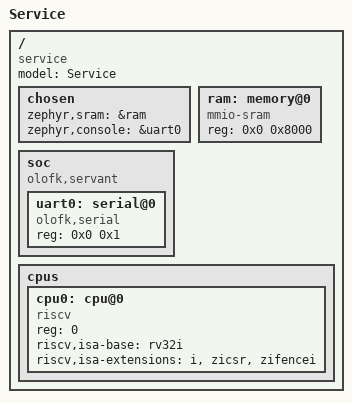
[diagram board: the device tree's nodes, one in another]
/*
 * Copyright (c) 2020 Olof Kindgren <olof.kindgren@gmail.com>
 *
 * SPDX-License-Identifier: Apache-2.0
 */

/dts-v1/;

#include <serv.dtsi>

/ {
	model = "Service";
	compatible = "service";

	chosen {
		zephyr,sram = &ram;
		zephyr,console = &uart0;
	};

	ram: memory@0 {
		compatible = "mmio-sram";
		reg = <0x0 0x8000>;
	};

	soc {
		compatible = "olofk,servant";
		#address-cells = <1>;
		#size-cells = <1>;

		uart0: serial@0 {
			reg = <0x0 0x1>;
			compatible = "olofk,serial";
		};
	};

	cpus {
		#address-cells = <1>;
		#size-cells = <0>;

		cpu0: cpu@0 {
			compatible = "riscv";
			reg = <0>;
			device_type = "cpu";
			riscv,isa-base = "rv32i";
			riscv,isa-extensions = "i", "zicsr", "zifencei";
		};
	};
};
